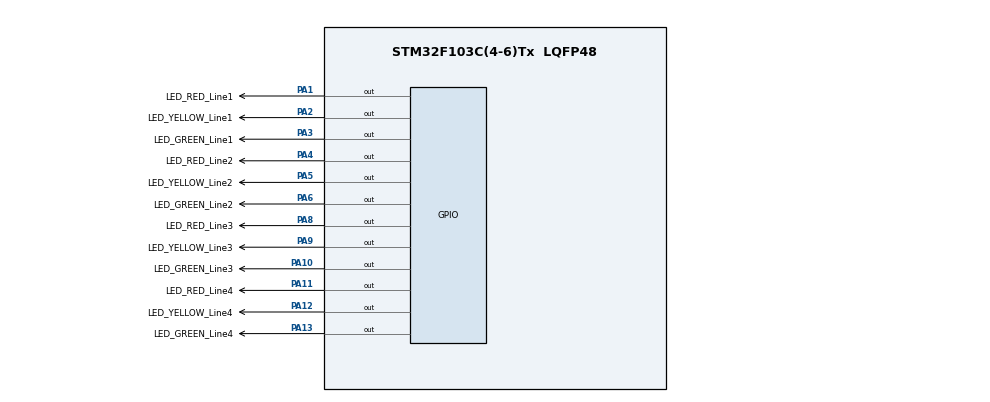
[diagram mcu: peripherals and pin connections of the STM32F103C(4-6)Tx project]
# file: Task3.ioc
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Mcu.Family=STM32F1
Mcu.Name=STM32F103C(4-6)Tx
Mcu.Package=LQFP48
NVIC.PriorityGroup=NVIC_PRIORITYGROUP_4
PA1.GPIO_Label=LED_RED_Line1
PA1.Signal=GPIO_Output
PA10.GPIO_Label=LED_GREEN_Line3
PA10.Signal=GPIO_Output
PA11.GPIO_Label=LED_RED_Line4
PA11.Signal=GPIO_Output
PA12.GPIO_Label=LED_YELLOW_Line4
PA12.Signal=GPIO_Output
PA13.GPIO_Label=LED_GREEN_Line4
PA13.Signal=GPIO_Output
PA2.GPIO_Label=LED_YELLOW_Line1
PA2.Signal=GPIO_Output
PA3.GPIO_Label=LED_GREEN_Line1
PA3.Signal=GPIO_Output
PA4.GPIO_Label=LED_RED_Line2
PA4.Signal=GPIO_Output
PA5.GPIO_Label=LED_YELLOW_Line2
PA5.Signal=GPIO_Output
PA6.GPIO_Label=LED_GREEN_Line2
PA6.Signal=GPIO_Output
PA8.GPIO_Label=LED_RED_Line3
PA8.Signal=GPIO_Output
PA9.GPIO_Label=LED_YELLOW_Line3
PA9.Signal=GPIO_Output
ProjectManager.HeapSize=0x200
ProjectManager.StackSize=0x400
ProjectManager.TargetToolchain=STM32CubeIDE
RCC.APB1Freq_Value=8000000
RCC.APB2Freq_Value=8000000
VP_SYS_VS_ND.Mode=No_Debug
board=custom

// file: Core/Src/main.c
/* USER CODE BEGIN Header */
/**
  ******************************************************************************
  * @file           : main.c
  * @brief          : Main program body
  ******************************************************************************
  * @attention
  *
  * <h2><center>&copy; Copyright (c) 2022 STMicroelectronics.
  * All rights reserved.</center></h2>
  *
  * This software component is licensed by ST under BSD 3-Clause license,
  * the "License"; You may not use this file except in compliance with the
  * License. You may obtain a copy of the License at:
  *                        opensource.org/licenses/BSD-3-Clause
  *
  ******************************************************************************
  */
/* USER CODE END Header */
#include "main.h"

void SystemClock_Config(void);
static void MX_GPIO_Init(void);

int main(void)
{

  /* MCU Configuration--------------------------------------------------------*/

  /* Reset of all peripherals, Initializes the Flash interface and the Systick. */
  HAL_Init();

  /* Configure the system clock */
  SystemClock_Config();

  /* Initialize all configured peripherals */
  MX_GPIO_Init();

  /* Infinite loop */
  /* USER CODE BEGIN WHILE */
  int counter  = 3;
  int led_status = 1;
  // State of Traffic Light
  /*
   * led_status = 1 => State 1
   * led_status = 2 => State 2
   * led_status = 3 => State 3
   * led_status = 4 => State 4
   *   */
  while (1)
  {
	  counter = counter -1 ;  // 3-> 2 ; 2-> 1 ; 1->0
    /* USER CODE END WHILE */
	  if(led_status == 1)
	  {
		  if(counter == 2 || counter ==1)
		  {
			  // State 1 : Line 1 : Green On, Line 2: Red on, Line 3: Green on, Line 4: Red on
			 		  	 	  HAL_GPIO_WritePin ( LED_RED_Line1_GPIO_Port , LED_RED_Line1_Pin , RESET );
			 		  	 	  HAL_GPIO_WritePin ( LED_RED_Line3_GPIO_Port , LED_RED_Line3_Pin , RESET );
			 		  	 	  HAL_GPIO_WritePin ( LED_YELLOW_Line1_GPIO_Port , LED_YELLOW_Line1_Pin , RESET );
			 		  		  HAL_GPIO_WritePin ( LED_YELLOW_Line3_GPIO_Port , LED_YELLOW_Line3_Pin , RESET );
			 		  	 	  HAL_GPIO_WritePin ( LED_GREEN_Line1_GPIO_Port , LED_GREEN_Line1_Pin , SET );
			 		  	 	  HAL_GPIO_WritePin ( LED_GREEN_Line3_GPIO_Port , LED_GREEN_Line3_Pin , SET );

			 		  	 	  HAL_GPIO_WritePin ( LED_YELLOW_Line2_GPIO_Port , LED_YELLOW_Line2_Pin , RESET );
			 		  	 	  HAL_GPIO_WritePin ( LED_YELLOW_Line4_GPIO_Port , LED_YELLOW_Line4_Pin , RESET );
			 		  	 	  HAL_GPIO_WritePin ( LED_GREEN_Line2_GPIO_Port , LED_GREEN_Line2_Pin , RESET );
			 		  	 	  HAL_GPIO_WritePin ( LED_GREEN_Line4_GPIO_Port , LED_GREEN_Line4_Pin , RESET );
			 		  	 	  HAL_GPIO_WritePin ( LED_RED_Line2_GPIO_Port , LED_RED_Line2_Pin , SET );
			 		  	 	  HAL_GPIO_WritePin ( LED_RED_Line4_GPIO_Port , LED_RED_Line4_Pin , SET );
		  }
		  if(counter == 0)
		  {
			  led_status = 2;
			  counter= 3;
		  }
	  }
	  if(led_status == 2)
	  {
		  counter = counter -1 ;  // 3-> 2 ; 2-> 1 ; 1->0
		  if(counter == 2 || counter ==1 )
		  {
			  // State 2 : Line 1 : Yellow On, Line 2: Red on, Line 3: Yellow on, Line 4: Red on
			  	 	 HAL_GPIO_WritePin ( LED_RED_Line2_GPIO_Port , LED_RED_Line2_Pin , SET );
			  	 	 HAL_GPIO_WritePin ( LED_RED_Line4_GPIO_Port , LED_RED_Line4_Pin , SET );
			  	 	 HAL_GPIO_WritePin ( LED_YELLOW_Line2_GPIO_Port , LED_YELLOW_Line2_Pin , RESET );
			  	     HAL_GPIO_WritePin ( LED_YELLOW_Line4_GPIO_Port , LED_YELLOW_Line4_Pin , RESET );
			  	 	 HAL_GPIO_WritePin ( LED_GREEN_Line2_GPIO_Port , LED_GREEN_Line2_Pin , RESET );
			  	 	 HAL_GPIO_WritePin ( LED_GREEN_Line4_GPIO_Port , LED_GREEN_Line4_Pin , RESET );

			  	 	  HAL_GPIO_WritePin ( LED_GREEN_Line1_GPIO_Port , LED_GREEN_Line1_Pin , RESET );
			  	 	  HAL_GPIO_WritePin ( LED_GREEN_Line3_GPIO_Port , LED_GREEN_Line3_Pin , RESET );
			  	 	  HAL_GPIO_WritePin ( LED_RED_Line1_GPIO_Port , LED_RED_Line1_Pin , RESET );
			  	 	  HAL_GPIO_WritePin ( LED_RED_Line3_GPIO_Port , LED_RED_Line3_Pin , RESET );
			  	 	  HAL_GPIO_WritePin ( LED_YELLOW_Line1_GPIO_Port , LED_YELLOW_Line1_Pin , SET );
			  	 	  HAL_GPIO_WritePin ( LED_YELLOW_Line3_GPIO_Port , LED_YELLOW_Line3_Pin , SET );
		  }
		  if(counter == 0)
		  {
			  led_status = 3;
			  counter= 3;
		  }
	  }
        if(led_status == 3)
        {
        	counter = counter -1 ;  // 3-> 2 ; 2-> 1 ; 1->0
        	if(counter == 2|| counter==1 )
        	{
        		// State 3 : Line 1 : Red On, Line 2: Green on, Line 3: Red on, Line 4: Green on
        			 	 HAL_GPIO_WritePin ( LED_RED_Line2_GPIO_Port , LED_RED_Line2_Pin , RESET );
        			 	 HAL_GPIO_WritePin ( LED_RED_Line4_GPIO_Port , LED_RED_Line4_Pin , RESET );
        			 	 HAL_GPIO_WritePin ( LED_YELLOW_Line2_GPIO_Port , LED_YELLOW_Line2_Pin , RESET );
        			 	 HAL_GPIO_WritePin ( LED_YELLOW_Line4_GPIO_Port , LED_YELLOW_Line4_Pin , RESET );
        			 	 HAL_GPIO_WritePin ( LED_GREEN_Line2_GPIO_Port , LED_GREEN_Line2_Pin , SET );
        			 	 HAL_GPIO_WritePin ( LED_GREEN_Line4_GPIO_Port , LED_GREEN_Line4_Pin , SET );

        			 	 HAL_GPIO_WritePin ( LED_GREEN_Line1_GPIO_Port , LED_GREEN_Line1_Pin , RESET );
        			 	 HAL_GPIO_WritePin ( LED_GREEN_Line3_GPIO_Port , LED_GREEN_Line3_Pin , RESET );
        			 	 HAL_GPIO_WritePin ( LED_RED_Line1_GPIO_Port , LED_RED_Line1_Pin , SET );
        			 	 HAL_GPIO_WritePin ( LED_RED_Line3_GPIO_Port , LED_RED_Line3_Pin , SET );
        			 	 HAL_GPIO_WritePin ( LED_YELLOW_Line1_GPIO_Port , LED_YELLOW_Line1_Pin , RESET );
        			 	 HAL_GPIO_WritePin ( LED_YELLOW_Line3_GPIO_Port , LED_YELLOW_Line3_Pin , RESET );
        	}
        	if(counter==0)
        	{
        		  led_status = 4;
        		  counter= 3;
        	}
        }
	     if(led_status == 4)
	     {
	    	 counter = counter -1;
	    	 if(counter == 2 || counter == 1)
	    	 {
	    		 // State 4 : Line 1 : Red On, Line 2: Yellow on, Line 3: Red on, Line 4: Yellow on

	    			 	 HAL_GPIO_WritePin ( LED_GREEN_Line1_GPIO_Port , LED_GREEN_Line1_Pin , RESET );
	    			 	 HAL_GPIO_WritePin ( LED_GREEN_Line3_GPIO_Port , LED_GREEN_Line3_Pin , RESET );
	    			 	 HAL_GPIO_WritePin ( LED_RED_Line1_GPIO_Port , LED_RED_Line1_Pin , SET );
	    			 	 HAL_GPIO_WritePin ( LED_RED_Line3_GPIO_Port , LED_RED_Line3_Pin , SET );
	    			 	 HAL_GPIO_WritePin ( LED_YELLOW_Line1_GPIO_Port , LED_YELLOW_Line1_Pin , RESET );
	    			 	 HAL_GPIO_WritePin ( LED_YELLOW_Line3_GPIO_Port , LED_YELLOW_Line3_Pin , RESET );

	    				 HAL_GPIO_WritePin ( LED_RED_Line2_GPIO_Port , LED_RED_Line2_Pin , RESET );
	    				 HAL_GPIO_WritePin ( LED_RED_Line4_GPIO_Port , LED_RED_Line4_Pin , RESET );
	    				 HAL_GPIO_WritePin ( LED_YELLOW_Line2_GPIO_Port , LED_YELLOW_Line2_Pin , SET );
	    				 HAL_GPIO_WritePin ( LED_YELLOW_Line4_GPIO_Port , LED_YELLOW_Line4_Pin , SET );
	    				 HAL_GPIO_WritePin ( LED_GREEN_Line2_GPIO_Port , LED_GREEN_Line2_Pin , RESET );
	    				 HAL_GPIO_WritePin ( LED_GREEN_Line4_GPIO_Port , LED_GREEN_Line4_Pin , RESET );
	    	 }
	    	 if(counter == 0)
	    	 {
	    		  led_status = 1;
	    		  counter= 3;
	    	 }
	     }
		 HAL_Delay (1000);
  }
}

void SystemClock_Config(void)
{
  RCC_OscInitTypeDef RCC_OscInitStruct = {0};
  RCC_ClkInitTypeDef RCC_ClkInitStruct = {0};

  /** Initializes the RCC Oscillators according to the specified parameters
  * in the RCC_OscInitTypeDef structure.
  */
  RCC_OscInitStruct.OscillatorType = RCC_OSCILLATORTYPE_HSI;
  RCC_OscInitStruct.HSIState = RCC_HSI_ON;
  RCC_OscInitStruct.HSICalibrationValue = RCC_HSICALIBRATION_DEFAULT;
  RCC_OscInitStruct.PLL.PLLState = RCC_PLL_NONE;
  if (HAL_RCC_OscConfig(&RCC_OscInitStruct) != HAL_OK)
  {
    Error_Handler();
  }
  /** Initializes the CPU, AHB and APB buses clocks
  */
  RCC_ClkInitStruct.ClockType = RCC_CLOCKTYPE_HCLK|RCC_CLOCKTYPE_SYSCLK
                              |RCC_CLOCKTYPE_PCLK1|RCC_CLOCKTYPE_PCLK2;
  RCC_ClkInitStruct.SYSCLKSource = RCC_SYSCLKSOURCE_HSI;
  RCC_ClkInitStruct.AHBCLKDivider = RCC_SYSCLK_DIV1;
  RCC_ClkInitStruct.APB1CLKDivider = RCC_HCLK_DIV1;
  RCC_ClkInitStruct.APB2CLKDivider = RCC_HCLK_DIV1;

  if (HAL_RCC_ClockConfig(&RCC_ClkInitStruct, FLASH_LATENCY_0) != HAL_OK)
  {
    Error_Handler();
  }
}

static void MX_GPIO_Init(void)
{
  GPIO_InitTypeDef GPIO_InitStruct = {0};

  /* GPIO Ports Clock Enable */
  __HAL_RCC_GPIOA_CLK_ENABLE();

  /*Configure GPIO pin Output Level */
  HAL_GPIO_WritePin(GPIOA, LED_RED_Line1_Pin|LED_YELLOW_Line1_Pin|LED_GREEN_Line1_Pin|LED_RED_Line2_Pin
                          |LED_YELLOW_Line2_Pin|LED_GREEN_Line2_Pin|LED_RED_Line3_Pin|LED_YELLOW_Line3_Pin
                          |LED_GREEN_Line3_Pin|LED_RED_Line4_Pin|LED_YELLOW_Line4_Pin|LED_GREEN_Line4_Pin, GPIO_PIN_RESET);

  /*Configure GPIO pins : LED_RED_Line1_Pin LED_YELLOW_Line1_Pin LED_GREEN_Line1_Pin LED_RED_Line2_Pin
                           LED_YELLOW_Line2_Pin LED_GREEN_Line2_Pin LED_RED_Line3_Pin LED_YELLOW_Line3_Pin
                           LED_GREEN_Line3_Pin LED_RED_Line4_Pin LED_YELLOW_Line4_Pin LED_GREEN_Line4_Pin */
  GPIO_InitStruct.Pin = LED_RED_Line1_Pin|LED_YELLOW_Line1_Pin|LED_GREEN_Line1_Pin|LED_RED_Line2_Pin
                          |LED_YELLOW_Line2_Pin|LED_GREEN_Line2_Pin|LED_RED_Line3_Pin|LED_YELLOW_Line3_Pin
                          |LED_GREEN_Line3_Pin|LED_RED_Line4_Pin|LED_YELLOW_Line4_Pin|LED_GREEN_Line4_Pin;
  GPIO_InitStruct.Mode = GPIO_MODE_OUTPUT_PP;
  GPIO_InitStruct.Pull = GPIO_NOPULL;
  GPIO_InitStruct.Speed = GPIO_SPEED_FREQ_LOW;
  HAL_GPIO_Init(GPIOA, &GPIO_InitStruct);

}

void Error_Handler(void)
{
  __disable_irq();
  while (1)
  {
  }
}

/************************ (C) COPYRIGHT STMicroelectronics *****END OF FILE****/
